# MPU_2 register map
Vendor: Texas Instruments
Peripheral module from a debugger description file (folder msp430).
Registers are 16-bit, read-write, reset 0x0 unless marked. A register's access mark holds for its fields unless they carry their own. Offsets are as the file gives them; lines under a group give offsets from that group; [hi:lo] are bit positions; {n}, {i} and the like mark numbered series; 'fields as' and 'values as' point back to an identical list; <NAME> marks a mode.

## MPU
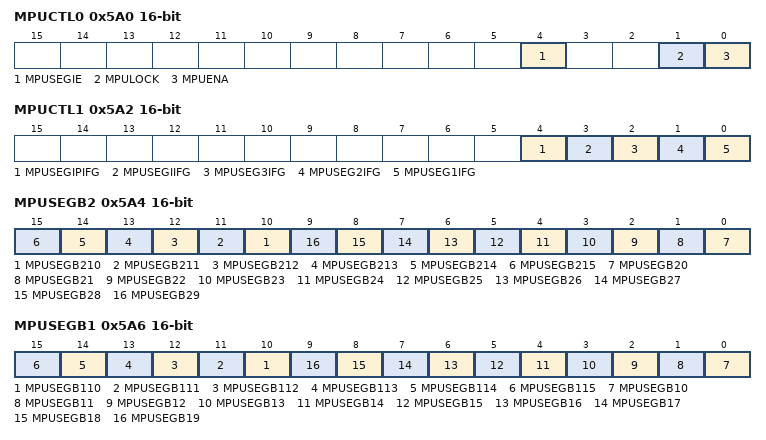
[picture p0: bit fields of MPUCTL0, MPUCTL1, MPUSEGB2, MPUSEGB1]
0x5A0 MPUCTL0 — MPU Control Register 0
  [4] MPUSEGIE — MPU Enable NMI on Segment violation
  [1] MPULOCK
  [0] MPUENA — MPU Enable
0x5A2 MPUCTL1 — MPU Control Register 1
  [4] MPUSEGIPIFG — MPU IP Memory Segment violation interupt flag
  [3] MPUSEGIIFG — MPU Info Memory Segment violation interupt flag
  [2] MPUSEG3IFG — MPU Main Memory Segment 3 violation interupt flag
  [1] MPUSEG2IFG — MPU Main Memory Segment 2 violation interupt flag
  [0] MPUSEG1IFG — MPU Main Memory Segment 1 violation interupt flag
0x5A4 MPUSEGB2 — MPU Segmentation Border 2 Register
  [n-200] MPUSEGB{n} (n=210..215) — MPU Segment Border 2 Bit: {n-200}
  [n-20] MPUSEGB{n} (n=20..29) — MPU Segment Border 2 Bit: {n-20}
0x5A6 MPUSEGB1 — MPU Segmentation Border 1 Register
  [n-100] MPUSEGB{n} (n=110..115) — MPU Segment Border 1 Bit: {n-100}
  [n-10] MPUSEGB{n} (n=10..19) — MPU Segment Border 1 Bit: {n-10}
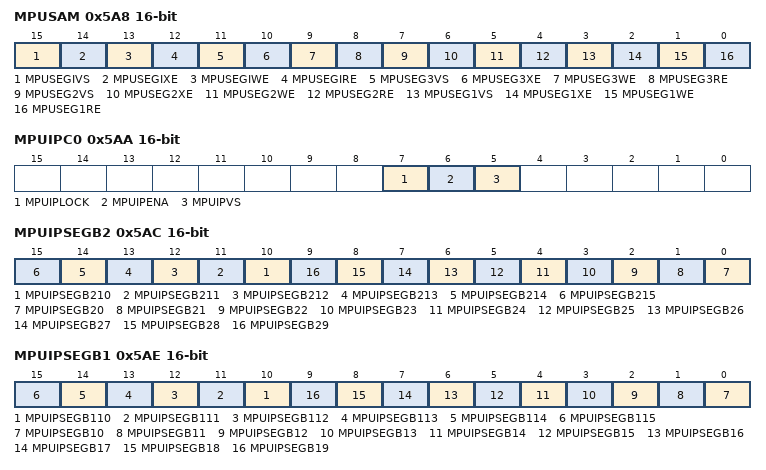
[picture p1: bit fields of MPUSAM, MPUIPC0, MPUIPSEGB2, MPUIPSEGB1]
0x5A8 MPUSAM — MPU Access Management Register
  [15] MPUSEGIVS — MPU Info memory Segment Violation select
  [14] MPUSEGIXE — MPU Info memory Segment Execute enable
  [13] MPUSEGIWE — MPU Info memory Segment Write enable
  [12] MPUSEGIRE — MPU Info memory Segment Read enable
  [11] MPUSEG3VS — MPU Main memory Segment 3 Violation select
  [10] MPUSEG3XE — MPU Main memory Segment 3 Execute enable
  [9] MPUSEG3WE — MPU Main memory Segment 3 Write enable
  [8] MPUSEG3RE — MPU Main memory Segment 3 Read enable
  [7] MPUSEG2VS — MPU Main memory Segment 2 Violation select
  [6] MPUSEG2XE — MPU Main memory Segment 2 Execute enable
  [5] MPUSEG2WE — MPU Main memory Segment 2 Write enable
  [4] MPUSEG2RE — MPU Main memory Segment 2 Read enable
  [3] MPUSEG1VS — MPU Main memory Segment 1 Violation select
  [2] MPUSEG1XE — MPU Main memory Segment 1 Execute enable
  [1] MPUSEG1WE — MPU Main memory Segment 1 Write enable
  [0] MPUSEG1RE — MPU Main memory Segment 1 Read enable
0x5AA MPUIPC0 — MPU IP Control 0 Register
  [7] MPUIPLOCK — MPU IP Protection Lock
  [6] MPUIPENA — MPU MPU IP Protection Enable
  [5] MPUIPVS — MPU MPU IP protection segment Violation Select
0x5AC MPUIPSEGB2 — MPU IP Segment Border 2 Register
  [n-200] MPUIPSEGB{n} (n=210..215) — MPU IP Segment Border 2 Bit: {n-200}
  [n-20] MPUIPSEGB{n} (n=20..29) — MPU IP Segment Border 2 Bit: {n-20}
0x5AE MPUIPSEGB1 — MPU IP Segment Border 1 Register
  [n-100] MPUIPSEGB{n} (n=110..115) — MPU IP Segment Border 1 Bit: {n-100}
  [n-10] MPUIPSEGB{n} (n=10..19) — MPU IP Segment Border 1 Bit: {n-10}
